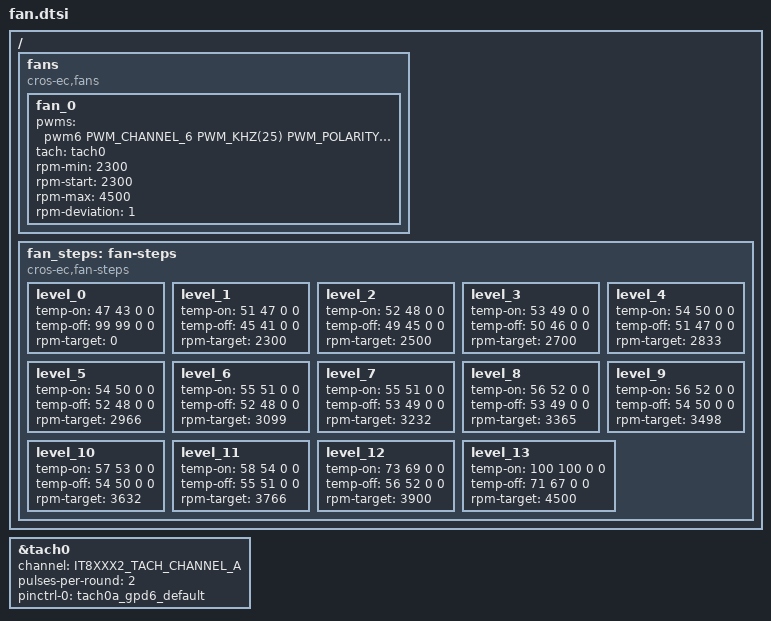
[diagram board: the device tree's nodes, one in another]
/* Copyright 2025 The ChromiumOS Authors
 * Use of this source code is governed by a BSD-style license that can be
 * found in the LICENSE file.
 */

/ {
	fans {
		compatible = "cros-ec,fans";
		fan_0 {
			pwms = <&pwm6 PWM_CHANNEL_6
				PWM_KHZ(25)
				PWM_POLARITY_NORMAL>;
			tach = <&tach0>;
			rpm-min = <2300>;
			rpm-start = <2300>;
			rpm-max = <4500>;
			rpm-deviation = <1>;
		};
	};

	fan_steps: fan-steps {
		compatible = "cros-ec,fan-steps";
		level_0 {
			temp-on = <47 43 0 0>;
			temp-off = <99 99 0 0>;
			rpm-target = <0>;
		};
		level_1 {
			temp-on = <51 47 0 0>;
			temp-off = <45 41 0 0>;
			rpm-target = <2300>;
		};
		level_2 {
			temp-on = <52 48 0 0>;
			temp-off = <49 45 0 0>;
			rpm-target = <2500>;
		};
		level_3 {
			temp-on = <53 49 0 0>;
			temp-off = <50 46 0 0>;
			rpm-target = <2700>;
		};
		level_4 {
			temp-on = <54 50 0 0>;
			temp-off = <51 47 0 0>;
			rpm-target = <2833>;
		};
		level_5 {
			temp-on = <54 50 0 0>;
			temp-off = <52 48 0 0>;
			rpm-target = <2966>;
		};
		level_6 {
			temp-on = <55 51 0 0>;
			temp-off = <52 48 0 0>;
			rpm-target = <3099>;
		};
		level_7 {
			temp-on = <55 51 0 0>;
			temp-off = <53 49 0 0>;
			rpm-target = <3232>;
		};
		level_8 {
			temp-on = <56 52 0 0>;
			temp-off = <53 49 0 0>;
			rpm-target = <3365>;
		};
		level_9 {
			temp-on = <56 52 0 0>;
			temp-off = <54 50 0 0>;
			rpm-target = <3498>;
		};
		level_10 {
			temp-on = <57 53 0 0>;
			temp-off = <54 50 0 0>;
			rpm-target = <3632>;
		};
		level_11 {
			temp-on = <58 54 0 0>;
			temp-off = <55 51 0 0>;
			rpm-target = <3766>;
		};
		level_12 {
			temp-on = <73 69 0 0>;
			temp-off = <56 52 0 0>;
			rpm-target = <3900>;
		};
		level_13 {
			temp-on = <100 100 0 0>;
			temp-off = <71 67 0 0>;
			rpm-target = <4500>;
		};
	};
};

/* fan tachometer sensor */
&tach0 {
	status = "okay";
	channel = <IT8XXX2_TACH_CHANNEL_A>;
	pulses-per-round = <2>;
	pinctrl-0 = <&tach0a_gpd6_default>;
	pinctrl-names = "default";
};
